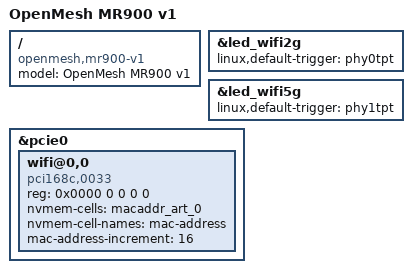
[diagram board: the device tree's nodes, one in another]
// SPDX-License-Identifier: GPL-2.0-or-later OR MIT

#include "qca9558_openmesh_mr.dtsi"

/ {
	compatible = "openmesh,mr900-v1", "qca,qca9558";
	model = "OpenMesh MR900 v1";
};

&led_wifi2g {
	linux,default-trigger = "phy0tpt";
};

&led_wifi5g {
	linux,default-trigger = "phy1tpt";
};

&pcie0 {
	wifi@0,0 {
		compatible = "pci168c,0033";
		reg = <0x0000 0 0 0 0>;
		nvmem-cells = <&macaddr_art_0>;
		nvmem-cell-names = "mac-address";
		mac-address-increment = <16>;
	};
};
